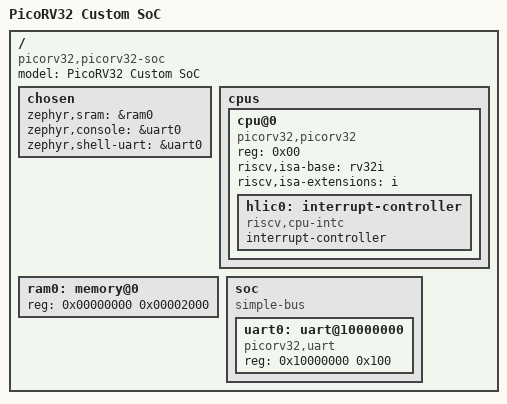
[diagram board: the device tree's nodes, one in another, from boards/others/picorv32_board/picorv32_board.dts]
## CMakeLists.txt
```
# CMakeLists.txt (application root)
# Registers our custom SoC/board/devicetree-binding directories with
# Zephyr's build system BEFORE find_package(Zephyr) runs, since that's
# when Zephyr scans these root variables.

cmake_minimum_required(VERSION 3.20.0)

list(APPEND BOARD_ROOT ${CMAKE_CURRENT_SOURCE_DIR})
list(APPEND SOC_ROOT ${CMAKE_CURRENT_SOURCE_DIR})
list(APPEND DTS_ROOT ${CMAKE_CURRENT_SOURCE_DIR})

find_package(Zephyr REQUIRED HINTS $ENV{ZEPHYR_BASE})
project(picorv32_zephyr_app)

target_sources(app PRIVATE src/main.c)
```

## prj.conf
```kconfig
# prj.conf
#
# CONFIG_SYS_CLOCK_EXISTS=n: this system genuinely has no interrupt-
# driving timer yet (picorv32_timer.v exists in hardware, but no
# Zephyr driver has been written for it -- that's deliberately a
# later step). This tells Zephyr's kernel honestly not to expect one,
# rather than us faking timer Kconfig values that don't reflect real
# hardware capability. Once a real timer driver exists, this line
# comes back out.
CONFIG_SYS_CLOCK_EXISTS=n
```

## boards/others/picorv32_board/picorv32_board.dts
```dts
/*
 * Devicetree for picorv32_board, adapted from Zephyr's own
 * qemu_riscv32 reference (dts/riscv/qemu/virt-riscv.dtsi +
 * virt-riscv32.dtsi), trimmed down to match this actual hardware:
 * single core, no CLINT/PLIC (interrupts not wired up yet), no
 * PCIe/virtio, and only the RV32I base ISA (matches every -march=rv32i
 * compile done so far -- no m/a/f/d/c/zicsr/zifencei claimed, since
 * the hardware hasn't been proven to support them).
 */

/dts-v1/;

/ {
	#address-cells = <0x01>;
	#size-cells = <0x01>;
	compatible = "picorv32,picorv32-soc";
	model = "PicoRV32 Custom SoC";

	chosen {
		zephyr,sram = &ram0;
		zephyr,console = &uart0;
		zephyr,shell-uart = &uart0;
	};

	cpus {
		#address-cells = <0x01>;
		#size-cells = <0x00>;

		cpu@0 {
			device_type = "cpu";
			reg = <0x00>;
			status = "okay";
			compatible = "picorv32,picorv32", "riscv";

			riscv,isa-base = "rv32i";
			riscv,isa-extensions = "i";

			hlic0: interrupt-controller {
				compatible = "riscv,cpu-intc";
				#address-cells = <0>;
				#interrupt-cells = <0x01>;
				interrupt-controller;
			};
		};
	};

	/* Matches picorv32_ram.v: 2048 words x 4 bytes = 0x2000 (8KB) */
	ram0: memory@0 {
		device_type = "memory";
		reg = <0x00000000 0x00002000>;
	};

	soc {
		#address-cells = <0x01>;
		#size-cells = <0x01>;
		compatible = "simple-bus";
		ranges;

		/* Matches picorv32_addr_decoder.v: UART at 0x10000000 */
		uart0: uart@10000000 {
			compatible = "picorv32,uart";
			reg = <0x10000000 0x100>;
			status = "okay";
		};
	};
};
```

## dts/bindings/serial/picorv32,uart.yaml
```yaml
# picorv32,uart.yaml
description: |
  Custom UART transmitter for the PicoRV32 SoC (see picorv32_uart_tx.v).
  Transmit-only, fixed baud rate set at synthesis time via the
  CLKS_PER_BIT Verilog parameter -- not software-configurable, so no
  current-speed property is used here.

compatible: "picorv32,uart"

include: [uart-controller.yaml]

properties:
  reg:
    required: true
```

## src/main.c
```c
/* main.c
 * Deliberately minimal for the first Zephyr build attempt on this
 * SoC -- no printk/console calls, since no UART driver exists yet
 * (only the devicetree binding). This isolates one thing at a time:
 * does the SoC/board/devicetree/Kconfig chain even resolve and link,
 * before adding driver complexity on top.
 */

int main(void)
{
	while (1) {
		/* nothing yet */
	}

	return 0;
}
```
